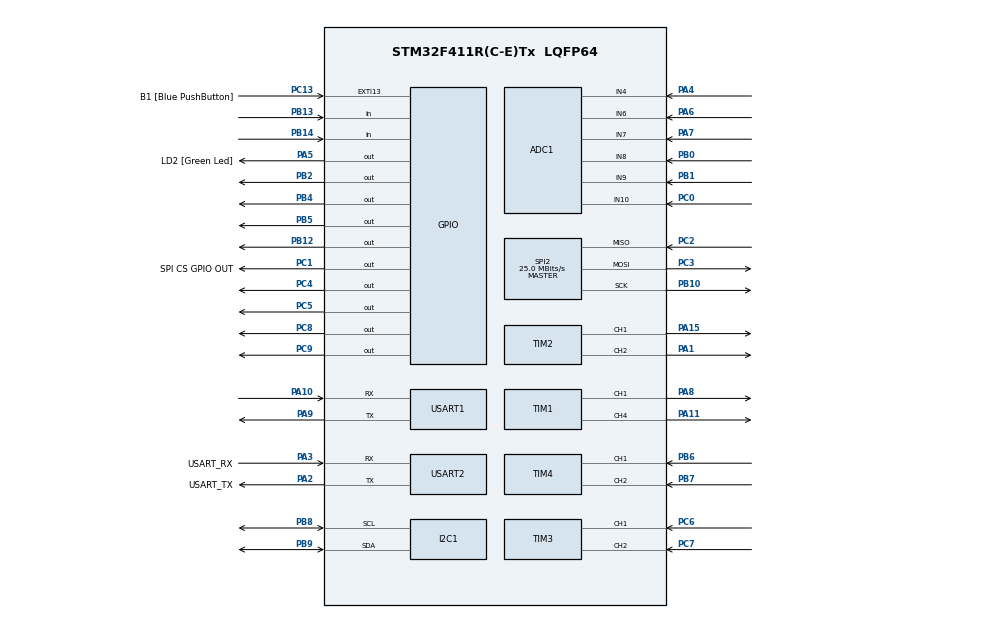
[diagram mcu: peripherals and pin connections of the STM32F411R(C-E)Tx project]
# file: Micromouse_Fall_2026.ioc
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ADC1.Channel-1\#ChannelRegularConversion=ADC_CHANNEL_10
ADC1.Channel-2\#ChannelRegularConversion=ADC_CHANNEL_4
ADC1.Channel-3\#ChannelRegularConversion=ADC_CHANNEL_6
ADC1.Channel-4\#ChannelRegularConversion=ADC_CHANNEL_7
ADC1.ContinuousConvMode=ENABLE
ADC1.DMAContinuousRequests=ENABLE
ADC1.NbrOfConversion=4
ADC1.NbrOfConversionFlag=1
ADC1.Rank-1\#ChannelRegularConversion=1
ADC1.Rank-2\#ChannelRegularConversion=2
ADC1.Rank-3\#ChannelRegularConversion=3
ADC1.Rank-4\#ChannelRegularConversion=4
ADC1.SamplingTime-1\#ChannelRegularConversion=ADC_SAMPLETIME_3CYCLES
ADC1.SamplingTime-2\#ChannelRegularConversion=ADC_SAMPLETIME_3CYCLES
ADC1.SamplingTime-3\#ChannelRegularConversion=ADC_SAMPLETIME_3CYCLES
ADC1.SamplingTime-4\#ChannelRegularConversion=ADC_SAMPLETIME_3CYCLES
ADC1.ScanConvMode=ENABLE
ADC1.master=1
Dma.ADC1.0.Direction=DMA_PERIPH_TO_MEMORY
Dma.ADC1.0.FIFOMode=DMA_FIFOMODE_DISABLE
Dma.ADC1.0.Instance=DMA2_Stream0
Dma.ADC1.0.MemDataAlignment=DMA_MDATAALIGN_HALFWORD
Dma.ADC1.0.MemInc=DMA_MINC_ENABLE
Dma.ADC1.0.Mode=DMA_CIRCULAR
Dma.ADC1.0.PeriphDataAlignment=DMA_PDATAALIGN_HALFWORD
Dma.ADC1.0.PeriphInc=DMA_PINC_DISABLE
Dma.ADC1.0.Priority=DMA_PRIORITY_HIGH
Dma.Request0=ADC1
FREERTOS.Tasks01=defaultTask,24,128,StartDefaultTask,Default,NULL,Dynamic,NULL,NULL
Mcu.Family=STM32F4
Mcu.Name=STM32F411R(C-E)Tx
Mcu.Package=LQFP64
NVIC.DMA2_Stream0_IRQn=true\:5\:0\:false\:false\:true\:true\:false\:true\:true
NVIC.PriorityGroup=NVIC_PRIORITYGROUP_4
NVIC.TIM1_TRG_COM_TIM11_IRQn=true\:5\:0\:false\:false\:true\:true\:true\:true\:true
NVIC.TIM1_UP_TIM10_IRQn=true\:15\:0\:false\:false\:true\:false\:false\:true\:true
NVIC.TimeBase=TIM1_UP_TIM10_IRQn
NVIC.TimeBaseIP=TIM10
PA1.Signal=S_TIM2_CH2
PA10.Mode=Asynchronous
PA10.Signal=USART1_RX
PA11.Signal=S_TIM1_CH4
PA13.GPIO_Label=TMS
PA13.Mode=Serial_Wire
PA13.Signal=SYS_JTMS-SWDIO
PA14.GPIO_Label=TCK
PA14.Mode=Serial_Wire
PA14.Signal=SYS_JTCK-SWCLK
PA15.Signal=S_TIM2_CH1_ETR
PA2.GPIO_Label=USART_TX
PA2.Mode=Asynchronous
PA2.Signal=USART2_TX
PA3.GPIO_Label=USART_RX
PA3.Mode=Asynchronous
PA3.Signal=USART2_RX
PA4.Signal=ADCx_IN4
PA5.GPIO_Label=LD2 [Green Led]
PA5.Signal=GPIO_Output
PA6.Signal=ADCx_IN6
PA7.Signal=ADCx_IN7
PA8.Signal=S_TIM1_CH1
PA9.Mode=Asynchronous
PA9.Signal=USART1_TX
PB0.Signal=ADCx_IN8
PB1.Signal=ADCx_IN9
PB10.Mode=Full_Duplex_Master
PB10.Signal=SPI2_SCK
PB12.Signal=GPIO_Output
PB13.Signal=GPIO_Input
PB14.Signal=GPIO_Input
PB2.Signal=GPIO_Output
PB3.GPIO_Label=SWO
PB3.Signal=SYS_JTDO-SWO
PB4.Signal=GPIO_Output
PB5.Signal=GPIO_Output
PB6.Signal=S_TIM4_CH1
PB7.Signal=S_TIM4_CH2
PB8.Mode=I2C
PB8.Signal=I2C1_SCL
PB9.Mode=I2C
PB9.Signal=I2C1_SDA
PC0.Signal=ADCx_IN10
PC1.GPIO_Label=SPI CS GPIO OUT
PC1.Signal=GPIO_Output
PC13-ANTI_TAMP.GPIO_Label=B1 [Blue PushButton]
PC13-ANTI_TAMP.GPIO_ModeDefaultEXTI=GPIO_MODE_IT_FALLING
PC13-ANTI_TAMP.Signal=GPXTI13
PC2.Mode=Full_Duplex_Master
PC2.Signal=SPI2_MISO
PC3.Mode=Full_Duplex_Master
PC3.Signal=SPI2_MOSI
PC4.Signal=GPIO_Output
PC5.Signal=GPIO_Output
PC6.Signal=S_TIM3_CH1
PC7.Signal=S_TIM3_CH2
PC8.Signal=GPIO_Output
PC9.Signal=GPIO_Output
PH0\ -\ OSC_IN.Mode=HSE-External-Oscillator
PH0\ -\ OSC_IN.Signal=RCC_OSC_IN
PH1\ -\ OSC_OUT.Mode=HSE-External-Oscillator
PH1\ -\ OSC_OUT.Signal=RCC_OSC_OUT
ProjectManager.HeapSize=0x200
ProjectManager.StackSize=0x400
ProjectManager.TargetToolchain=CMake
RCC.48MHZClocksFreq_Value=100000000
RCC.AHBFreq_Value=100000000
RCC.APB1CLKDivider=RCC_HCLK_DIV2
RCC.APB1Freq_Value=50000000
RCC.APB1TimFreq_Value=100000000
RCC.APB2Freq_Value=100000000
RCC.APB2TimFreq_Value=100000000
RCC.CortexFreq_Value=100000000
RCC.EnbaleCSS=true
RCC.FLatency-AdvancedSettings=FLASH_LATENCY_3
RCC.HCLKFreq_Value=100000000
RCC.HSE_VALUE=16000000
RCC.HSI_VALUE=16000000
RCC.LSE_VALUE=32768
RCC.PLLM=8
RCC.PLLN=200
RCC.PLLP=RCC_PLLP_DIV4
RCC.PLLSourceVirtual=RCC_PLLSOURCE_HSE
RCC.SYSCLKFreq_VALUE=100000000
RCC.SYSCLKSource=RCC_SYSCLKSOURCE_PLLCLK
RCC.VCOOutputFreq_Value=400000000
SH.ADCx_IN10.0=ADC1_IN10,IN10
SH.ADCx_IN4.0=ADC1_IN4,IN4
SH.ADCx_IN6.0=ADC1_IN6,IN6
SH.ADCx_IN7.0=ADC1_IN7,IN7
SH.ADCx_IN8.0=ADC1_IN8,IN8
SH.ADCx_IN9.0=ADC1_IN9,IN9
SH.S_TIM1_CH1.0=TIM1_CH1,PWM Generation1 CH1
SH.S_TIM1_CH4.0=TIM1_CH4,PWM Generation4 CH4
SH.S_TIM2_CH1_ETR.0=TIM2_CH1,PWM Generation1 CH1
SH.S_TIM2_CH2.0=TIM2_CH2,PWM Generation2 CH2
SH.S_TIM3_CH1.0=TIM3_CH1,Encoder_Interface
SH.S_TIM3_CH2.0=TIM3_CH2,Encoder_Interface
SH.S_TIM4_CH1.0=TIM4_CH1,Encoder_Interface
SH.S_TIM4_CH2.0=TIM4_CH2,Encoder_Interface
SPI2.BaudRatePrescaler=SPI_BAUDRATEPRESCALER_2
SPI2.CalculateBaudRate=25.0 MBits/s
SPI2.Direction=SPI_DIRECTION_2LINES
SPI2.Mode=SPI_MODE_MASTER
SPI2.VirtualType=VM_MASTER
TIM1.Channel-PWM\ Generation1\ CH1=TIM_CHANNEL_1
TIM1.Channel-PWM\ Generation4\ CH4=TIM_CHANNEL_4
TIM2.Channel-PWM\ Generation1\ CH1=TIM_CHANNEL_1
TIM2.Channel-PWM\ Generation2\ CH2=TIM_CHANNEL_2
USART1.VirtualMode=VM_ASYNC
USART2.VirtualMode=VM_ASYNC
VP_FREERTOS_VS_CMSIS_V2.Mode=CMSIS_V2
VP_SYS_VS_tim10.Mode=TIM10
VP_TIM11_VS_ClockSourceINT.Mode=Enable_Timer
board=NUCLEO-F411RE

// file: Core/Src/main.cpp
/* USER CODE BEGIN Header */
/**
  ******************************************************************************
  * @file           : main.c
  * @brief          : Main program body
  ******************************************************************************
  * @attention
  *
  * Copyright (c) 2026 STMicroelectronics.
  * All rights reserved.
  *
  * This software is licensed under terms that can be found in the LICENSE file
  * in the root directory of this software component.
  * If no LICENSE file comes with this software, it is provided AS-IS.
  *
  ******************************************************************************
  */
/* USER CODE END Header */
#include "main.h"
#include "cmsis_os.h"
#include "FreeRTOS.h"
#include "stm32f4xx_hal_i2c.h"
#include "task.h"
#include "queue.h"
#include "semphr.h"
#include "adc.h"
#include "dma.h"
#include "gpio.h"
#include "i2c.h"
#include "spi.h"
#include "tim.h"
#include "usart.h"
#include "system_clock.h"
#include "gpio.hpp"
#include "motor_driver.h"
#include "i2c1.h"
#include "adc1.h"
#include "IR_sensors.hpp"

void StartDefaultTask(void *argument);
void IR_sensor_task(void *argument);
void BLE_telemetry_task(void *arguement);
void IMU_task(void *arguement);

struct IR_readings{
    uint16_t right_IR_sensor;
    uint16_t left_IR_sensor;
    uint16_t front_left_IR_sensor;
    uint16_t front_right_IR_sensor;
};

QueueHandle_t irQueue;

int main(void)
{
  /* Reset of all peripherals, Initializes the Flash interface and the Systick. */
  HAL_Init();

  /* Configure the system clock */
  SystemClock_Config();

  /* Initialize all configured peripherals */
  MX_GPIO_Init();
  MX_DMA_Init();
  MX_USART2_UART_Init();
  MX_USART1_UART_Init();
  MX_ADC1_Init();
  MX_I2C1_Init();
  MX_SPI2_Init();
  MX_TIM1_Init();
  MX_TIM2_Init();
  MX_TIM3_Init();
  MX_TIM4_Init();
  MX_TIM11_Init();

  /* Create the thread(s) */
  /* creation of defaultTask */
  BaseType_t result = xTaskCreate(
    StartDefaultTask,
    "defaultTask",
    512,
    NULL,
    2,
    NULL
  );

  if (result != pdPASS) {
    Error_Handler();
  }

  BaseType_t result2 = xTaskCreate(
      IR_sensor_task,
      "IR_sensors",
      128,
      NULL,
      4,
      NULL
  );

  if (result2 != pdPASS) {
    Error_Handler();
  }

  BaseType_t result3 = xTaskCreate(
      BLE_telemetry_task,
      "Bluetooth telemetry",
      128,
      NULL,
      1,
      NULL
  );

  if (result3 != pdPASS) {
    Error_Handler();
  }

  BaseType_t result4 = xTaskCreate(
      IMU_task,
      "IMU",
      128,
      NULL,
      3,
      NULL
  );

  if (result4 != pdPASS) {
    Error_Handler();
  }

  irQueue = xQueueCreate(1, sizeof(IR_readings));

  if (irQueue == NULL) {
    Error_Handler();
  }

  /* Init scheduler */
  vTaskStartScheduler();

  /* We should never get here as control is now taken by the scheduler */
  Error_Handler();
  /* Infinite loop */
  while (1)
  {

  }
}

void StartDefaultTask(void *argument)
{
  /* Infinite loop */
  GPIO LED(GPIOA,GPIO_PIN_5);
  motor_init();
  while(1)
  {
    motor_brake();
    LED.toggle();
    vTaskDelay(500);
  }
}

void IR_sensor_task(void *argument)
{
  GPIO IR_LED1(GPIOB, GPIO_PIN_2);
  GPIO IR_LED2(GPIOB, GPIO_PIN_4);
  GPIO IR_LED3(GPIOB, GPIO_PIN_5);
  GPIO IR_LED4(GPIOB, GPIO_PIN_12);

  ADC1_Init();
  Delay_US_Init();

  enum IR_Receiver
  {
      IR_OUT_1 = 10,
      IR_OUT_2 = 4,
      IR_OUT_3 = 6,
      IR_OUT_4 = 7
  };

  IR_readings readings{};

  //what time is it right now
  TickType_t lastWakeTime = xTaskGetTickCount();

  /* Infinite loop */
  while(1)
  {
    //these may be mismatched, check during testing
    readings.right_IR_sensor = IR_Read(IR_LED1, IR_OUT_1);
    readings.left_IR_sensor = IR_Read(IR_LED2, IR_OUT_2);
    readings.front_right_IR_sensor = IR_Read(IR_LED3, IR_OUT_3);
    readings.front_left_IR_sensor = IR_Read(IR_LED4, IR_OUT_4);

    xQueueOverwrite(irQueue, &readings);

    //task sleeps until lastwaketime + 10 ticks
    vTaskDelayUntil(&lastWakeTime, pdMS_TO_TICKS(10));
  }
}

void BLE_telemetry_task(void *argument)
{
  /* USER CODE BEGIN 5 */

  /* Infinite loop */
  while(1)
  {
    vTaskDelay(10);
  }
  /* USER CODE END 5 */
}

void IMU_task(void *argument)
{
  /* USER CODE BEGIN 5 */

  /* Infinite loop */
  while(1)
  {
    vTaskDelay(10);
  }
  /* USER CODE END 5 */
}

void HAL_TIM_PeriodElapsedCallback(TIM_HandleTypeDef *htim)
{
  if (htim->Instance == TIM10)
  {
    HAL_IncTick();
  }
}

void Error_Handler(void)
{
  __disable_irq();
  while (1)
  {
  }
}
